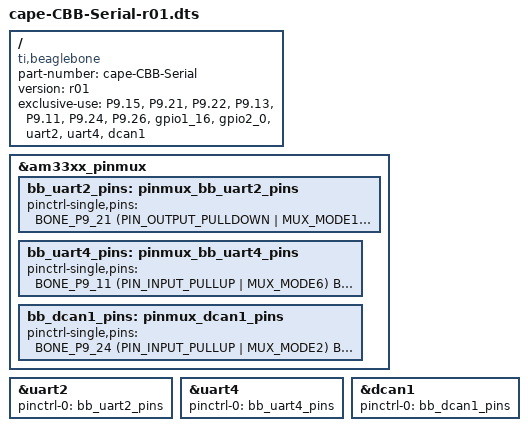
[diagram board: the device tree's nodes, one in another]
/* cape-CBB-Serial-r01.dts
 * Written by Alexander Hiam <hiamalexander@gmail.com>
 * for Logic Supply - http://logicsupply.com
 * Jan 28, 2014
 *
 * This is the Device Tree overlay for the CBB-Serial BeagleBone and
 * BeagleBone Black cape. It will enable the UART2, UART4 and DCAN1
 * interfaces, as well as mux GPIO1_16 for userspace control for
 * using software control of the RS485 receiver/driver enable.
 *
 * Note: the BeagleBone Black has GPIO1_16 tied to GPIO2_0 (which
 * is not exposed on the header), so this overlay muxes and controls
 * both pins.
 *
 * Copyright (c) 2014 - Logic Supply (http://logicsupply.com)
 * This program is free software; you can redistribute it and/or modify
 * it under the terms of the GNU General Public License version 2 as
 * published by the Free Software Foundation.
 */
/dts-v1/;
/plugin/;

#include <dt-bindings/board/am335x-bbw-bbb-base.h>
#include <dt-bindings/pinctrl/am33xx.h>

/ {
	compatible = "ti,beaglebone", "ti,beaglebone-black", "ti,beaglebone-green";

	/* identification */
	part-number = "cape-CBB-Serial";
	version = "r01";

	/* state the resources this cape uses */
	exclusive-use =
		/* the pin header uses */
		"P9.15", /* GPIO1_16 */

		"P9.21", /* uart2_txd */
		"P9.22", /* uart2_rxd */

		"P9.13", /* uart4_txd */
		"P9.11", /* uart4_rxd */

		"P9.24", /* dcan1_rx */
		"P9.26", /* dcan1_tx */

		/* the hardware ip uses */
		"gpio1_16",
		"gpio2_0",
		"uart2",
		"uart4",
		"dcan1";

	fragment@0 {
		target = <&am33xx_pinmux>;
		__overlay__ {
			bb_uart2_pins: pinmux_bb_uart2_pins {
				pinctrl-single,pins = <
					BONE_P9_21 (PIN_OUTPUT_PULLDOWN | MUX_MODE1) /* spi0_d0.uart2_txd */
					BONE_P9_22 (PIN_INPUT_PULLUP | MUX_MODE1) /* spi0_sclk.uart2_rxd */
				>;
			};

			bb_uart4_pins: pinmux_bb_uart4_pins {
				pinctrl-single,pins = <
					BONE_P9_11 (PIN_INPUT_PULLUP | MUX_MODE6) /* gpmc_wait0.uart4_rxd_mux2 */
					BONE_P9_13 (PIN_OUTPUT_PULLDOWN | MUX_MODE6) /* gpmc_wpn.uart4_txd_mux2 */
					BONE_P9_15 (PIN_INPUT | MUX_MODE7) /* gpmc_a0.gpio1[16] */
					0x088 (PIN_INPUT | MUX_MODE7) /* gpmc_csn3.gpio2[0] */
				>;
			};

			bb_dcan1_pins: pinmux_dcan1_pins {
				pinctrl-single,pins = <
					BONE_P9_24 (PIN_INPUT_PULLUP | MUX_MODE2) /* uart1_txd.d_can1_rx */
					BONE_P9_26 (PIN_OUTPUT_PULLUP | MUX_MODE2) /* uart1_rxd.d_can1_tx */
				>;
			};
		};
	};

	fragment@1 {
		target = <&uart2>;
		__overlay__ {
			status = "okay";
			pinctrl-names = "default";
			pinctrl-0 = <&bb_uart2_pins>;
		};
	};

	fragment@2 {
		target = <&uart4>;
		__overlay__ {
			status = "okay";
			pinctrl-names = "default";
			pinctrl-0 = <&bb_uart4_pins>;
		};
	};

	fragment@3 {
		target = <&dcan1>;
		__overlay__ {
			status = "okay";
			pinctrl-names = "default";
			pinctrl-0 = <&bb_dcan1_pins>;
		};
	};
};
